# ATA5702M322 device description
Architecture: AVR8; Family: megaAVR
Registers are 8-bit, access not given, no defined reset value unless marked. A register's access mark holds for its fields unless they carry their own. Offsets are from the block's base; [hi:lo] are bit positions; {n}, {i} and the like mark numbered series.

## CRC
Instances: CRC 0x00
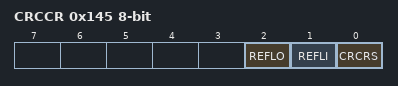
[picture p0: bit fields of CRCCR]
0x145 CRCCR — CRC Control Register
  [2] REFLO — Reflect Data Output Byte
  [1] REFLI — Reflect Data Input Byte
  [0] CRCRS — CRC Data Register Reset
0x146 CRCDOR — CRC Data Output Register
0x1E0 CRCDIR — CRC Data Input Register

## DEBOUNCE
Instances: DEBOUNCE 0x00
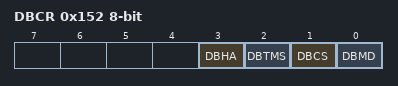
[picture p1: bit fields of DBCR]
0x152 DBCR — DeBounce Control Register
  [3] DBHA — Debounce Handshake Active
  [2] DBTMS — Debounce Timer Mask Select
  [1] DBCS — Debounce Clock Select
  [0] DBMD — Debounce Mode
0x153 DBTC — Debounce Timer Compare Register
0x154 DBENB — DeBounce Enable Port B
0x155 DBENC bits used 2:0 — DeBounce Enable Port C
0x164 DBEND — DeBounce Enable Port D

## DEBUG
Instances: DEBUG 0x00
0xFC TRCID 16-bit — Trace ID Register
0xFF TRCDR — Trace Data Register
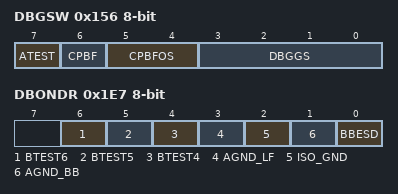
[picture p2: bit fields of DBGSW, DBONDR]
0x156 DBGSW — Debugging Support Switch
  [7] ATEST — Analog Test Pins Enable
  [6] CPBF — CPU Busy Flag
  [5:4] CPBFOS — CPU Busy Flag Output Select
    0=DISABLED; 1=PB0; 2=PB3; 3=PC1
  [3:0] DBGGS — Debugging Support Group Select
0x1E7 DBONDR — Downbond Test Register
  [6] BTEST6 — Bond Test 6
  [5] BTEST5 — Bond Test 5
  [4] BTEST4 — Bond Test 4
  [3] AGND_LF — Bond AGND LF
  [2] ISO_GND — Bond ISO SUBS3 GND
  [1] AGND_BB — Bond AGND BB
  [0] BBESD — Bond BBESD

## DFIFO
Instances: DFIFO 0x00
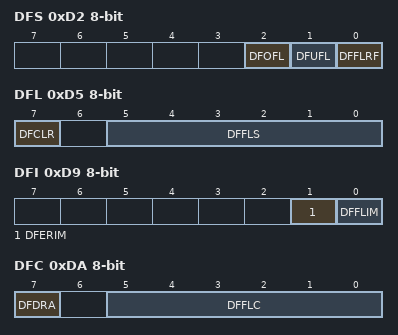
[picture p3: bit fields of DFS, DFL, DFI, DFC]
0xD2 DFS — Data FIFO Status Register
  [2] DFOFL — Data FIFO Overflow Flag
  [1] DFUFL — Data FIFO Underflow Flag
  [0] DFFLRF — Data FIFO Fill-Level Reached Status Flag
0xD5 DFL — Data FIFO Fill Level Register
  [7] DFCLR — Data FIFO Clear
  [5:0] DFFLS — Data FIFO Fill Level Status
0xD6 DFWP bits used 5:0 — Data FIFO Write Pointer
0xD7 DFRP bits used 5:0 — Data FIFO Read Pointer
0xD8 DFD — Data FIFO Data Register
0xD9 DFI — Data FIFO Interrupt Mask Register
  [1] DFERIM — Data FIFO Error Interrupt Mask
  [0] DFFLIM — Data FIFO Fill-level Interrupt Mask
0xDA DFC — Data FIFO Configuration Register
  [7] DFDRA — Data FIFO Direct Read Access Operational Mode
  [5:0] DFFLC — Data FIFO Fill-Level Configuration

## EEPROM
Instances: EEPROM 0x00
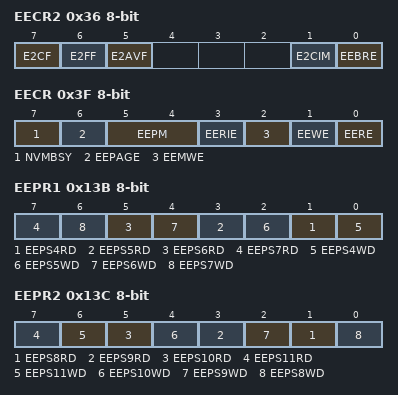
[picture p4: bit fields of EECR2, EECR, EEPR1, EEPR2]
0x36 EECR2 — EEPROM Control Register 2
  [7] E2CF — EEPROM Error Correction Code Flag
  [6] E2FF — EEPROM error Fault Flag bit
  [5] E2AVF — EEPROM Access Violation Flag
  [1] E2CIM — EEPROM Error Code Correction Interrupt Mask
  [0] EEBRE — EEPROM Burst Read Enable
0x3F EECR — EEPROM Control Register
  [7] NVMBSY — Non-volatile memory busy
  [6] EEPAGE — EEPROM page access (multiple bytes access mode)
  [5:4] EEPM — EEPROM Programming Mode
    0=ERASE_AND_WRITE_IN_ONE_OPERATION; 1=ERASE_ONLY; 2=WRITE_ONLY
  [3] EERIE — EEPROM Ready Interrupt Enable
  [2] EEMWE — EEPROM Master Write Enable
  [1] EEWE — EEPROM Write Enable
  [0] EERE — EEPROM Read Enable
0x40 EEDR — EEPROM Data Register
0x41 EEAR 16-bit bits used 11:0 — EEPROM Address Register
0x43 EEPR — EEPROM Protection Register
  [3:0] EEAP — EEPROM Access Protection
0x13B EEPR1 — EEPROM Protection Register 1
  [2n-7] EEPS{n}RD (n=4..7) — EEPROM Protection Section {n} Read Disable
  [2n-8] EEPS{n}WD (n=4..7) — EEPROM Protection Section {n} Write Disable
0x13C EEPR2 — EEPROM Protection Register 2
  [2n-15] EEPS{n}RD (n=8..11) — EEPROM Protection Section {n} Read Disable
  [6] EEPS11WD — EEPROM Protection Section 11 Write Disable
  [4] EEPS10WD — EEPROM Protection Section 10 Write Disableble
  [2] EEPS9WD — EEPROM Protection Section 9 Write Disable
  [0] EEPS8WD — EEPROM Protection Section 8 Write Disable
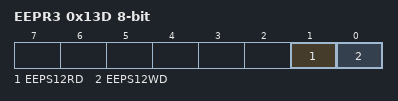
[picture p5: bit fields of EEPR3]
0x13D EEPR3 — EEPROM Protection Register 3
  [1] EEPS12RD — EEPROM Protection Section 12 Read Disable
  [0] EEPS12WD — EEPROM Protection Section 12 Write Disable

## FE
Instances: FE 0x00
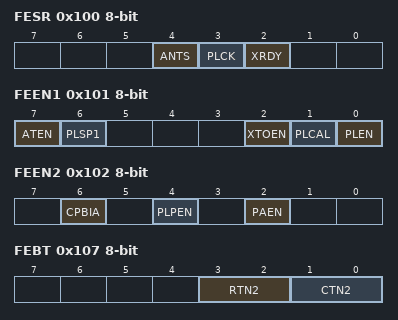
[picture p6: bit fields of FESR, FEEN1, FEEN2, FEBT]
0x100 FESR — Front-End Status Register
  [4] ANTS — Antenna saturated
  [3] PLCK — PLL locked
  [2] XRDY — XTO ready
0x101 FEEN1 — Front-End Enable Register 1
  [7] ATEN — Antenna Tuning Enable
  [6] PLSP1 — PLL Speedup 1
  [2] XTOEN — Cristal Oscillator enable
  [1] PLCAL — PLL calibration mode
  [0] PLEN — PLL enable
0x102 FEEN2 — Front-End Enable Register 2
  [6] CPBIA — Cap Array Bias
  [4] PLPEN — PLL Post En IQ divider
  [2] PAEN — Power Amplifier enable
0x103 FELNA — Reserved
0x104 FEAT — Front-End Antenna Tuning
  [3:0] ANTN — Antenna Tuning
0x105 FEPAC — Front-End Power Amplifier Control Register
  [7:0] PACR — Front-End Power Amplifier Control Register Pout/dBm LowBand HighBand
    0=_11_80_12_90; 1=_11_30_12_33; 2=_10_70_11_76; 3=_10_20_11_10; 4=_9_70_10_60; 5=_9_20_10_00; 6=_8_60_9_50; 7=_8_00_9_00; 8=_7_50_8_50; 9=_7_00_7_90; 10=_6_40_7_30; 11=_5_90_6_80; 12=_5_30_6_30; 13=_4_77_5_70; 14=_4_17_5_20; 15=_3_67_4_60; 16=_3_12_4_07; 17=_2_56_3_47; 18=_2_10_2_97; 19=_1_58_2_42; 20=_1_08_1_86; 21=_0_50_1_40; 22=_0_00_0_88; 23=_0_41_0_38; 24=_1_00_0_20; 25=_1_42_0_70; 26=_1_83_1_11; 27=_2_42_1_70; 28=_2_88_2_12; 29=_3_38_2_53; 30=_3_81_3_12; 31=_4_31_3_58; 32=_4_72_4_08; 33=_5_09_4_51; 34=_5_57_5_01; 35=_6_00_5_42; 36=_6_41_5_79; 37=_6_77_6_27; 38=_7_19_6_70; 39=_7_55_7_11; 40=_7_98_7_47; 41=_8_40_7_89; 42=_8_79_8_25; 43=_9_11_8_68; 44=_9_46_9_10; 45=_9_82_9_49; 46=_10_18_9_81; 47=_10_60_10_16; 48=_10_89_10_52; 49=_11_30_10_88; 50=_11_62_11_30; 51=_12_06_11_59; 52=_12_39_12_00; 53=_12_82_12_32; 54=_13_22_12_76; 55=_13_58_13_09; 56=_13_95_13_52; 57=_14_22_13_92; 58=_14_41_14_28; 59=_14_49_14_65; {v}=_14_60_14_65 (v=60..63)
0x106 FEVCT bits used 3:0 — Front-End VCO Tuning Register
0x107 FEBT — Front-End RC Tuning Register
  [3:2] RTN2 — Resistor Tuning
  [1:0] CTN2 — Capacitor Tuning
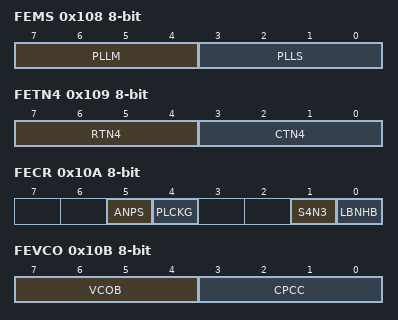
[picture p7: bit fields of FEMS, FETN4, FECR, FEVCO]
0x108 FEMS — Front-End Main and Swallow Control Register
  [7:4] PLLM — PLL Mode
  [3:0] PLLS — PLL Swallow
0x109 FETN4 — Front-End RC Tuning 4bit Register
  [7:4] RTN4 — 4 bit Resistor Tuning
  [3:0] CTN4 — 4 bit Capacitor Tuning
0x10A FECR — Front-End Control Register
  [5] ANPS — ASK Not DPSK Switch
  [4] PLCKG — PLL Lock Detect Gate
  [1] S4N3 — Select 433 Not 315MHz Band
  [0] LBNHB — Select Low-Band Not High-Band
0x10B FEVCO — Front-End VCO and PLL control
  [7:4] VCOB — VCO Bias
  [3:0] CPCC — Charge pump current control
0x10C FEALR — Front-End Antenna Level Detector Range
  [1:0] RNGE — Range of the ANT_TUNE level detector
    0=0_3_DBM; 1=4_7_DBM; 2=8_14_DBM; 3=SECURE_MEASUREMENT
0x10D FEANT — Front-End Antenna
  [3:0] LVLC — antenna signal LeVeL
0x10E FEBIA — Reserved
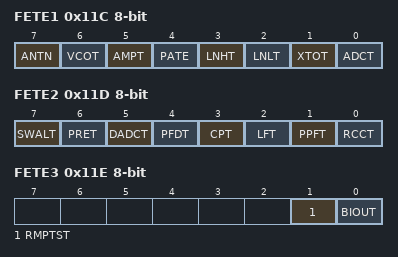
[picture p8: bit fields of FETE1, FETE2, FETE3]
0x11C FETE1 — Front-End Test Enable Register 1
  [7] ANTN, [6] VCOT, [5] AMPT, [4] PATE, [3] LNHT, [2] LNLT, [1] XTOT, [0] ADCT
0x11D FETE2 — Front-End Test Enable Register 2
  [7] SWALT, [6] PRET, [5] DADCT, [4] PFDT, [3] CPT, [2] LFT, [1] PPFT, [0] RCCT
0x11E FETE3 — Front-End Test Enable Register 3
  [1] RMPTST, [0] BIOUT
0x11F FETD — Front-End Test Data Register
